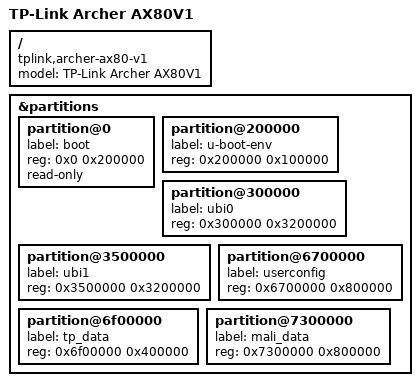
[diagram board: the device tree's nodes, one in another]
// SPDX-License-Identifier: (GPL-2.0 OR MIT)

/dts-v1/;
#include "mt7986a-tplink-archer-ax80-v1-common.dtsi"

/ {
	compatible = "tplink,archer-ax80-v1", "mediatek,mt7986a";
	model = "TP-Link Archer AX80V1";
};

&partitions {
	partition@0 {
		label = "boot";
		reg = <0x0 0x200000>;
		read-only;
	};
	
	partition@200000 {
		label = "u-boot-env";
		reg = <0x200000 0x100000>;
	};
	
	partition@300000 {
		label = "ubi0";
		reg = <0x300000 0x3200000>;
	};
	
	partition@3500000 {
		label = "ubi1";
		reg = <0x3500000 0x3200000>;
	};
	
	partition@6700000 {
		label = "userconfig";
		reg = <0x6700000 0x800000>;
	};
	
	partition@6f00000 {
		label = "tp_data";
		reg = <0x6f00000 0x400000>;
	};
	
	partition@7300000 {
		label = "mali_data";
		reg = <0x7300000 0x800000>;
	};
};
